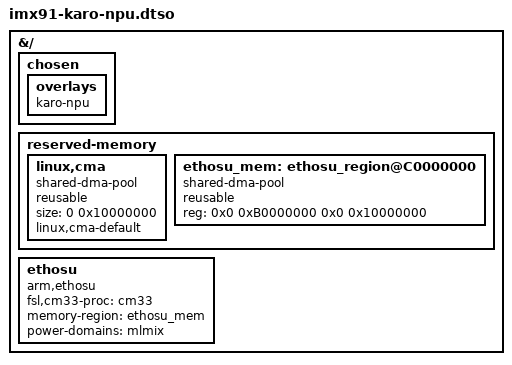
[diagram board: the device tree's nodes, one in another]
// SPDX-License-Identifier: (GPL-2.0+ OR MIT)
/*
 * Copyright (C) 2023 Lothar Waßmann <LW@KARO-electronics.de>
 */

/dts-v1/;
/plugin/;

&{/} {
	chosen {
		overlays {
			karo-npu;
		};
	};

	reserved-memory {
		#address-cells = <2>;
		#size-cells = <2>;
		ranges;

		linux,cma {
			compatible = "shared-dma-pool";
			reusable;
			//alloc-ranges = <0 0x80000000 0 0x40000000>;
			size = <0 0x10000000>;
			linux,cma-default;
		};

		ethosu_mem: ethosu_region@C0000000 {
			compatible = "shared-dma-pool";
			reusable;
			reg = <0x0 0xB0000000 0x0 0x10000000>;
		};
	};

	ethosu {
		compatible = "arm,ethosu";
		fsl,cm33-proc = <&cm33>;
		memory-region = <&ethosu_mem>;
		power-domains = <&mlmix>;
	};
};
